# MSP430FR5962 register map
File version: 2.1
CPU: MSP430FR5962 r2p1, little endian, MPU, no FPU, 3 interrupt priority bits
Registers are 16-bit, read-write, reset 0x0 unless marked. A register's access mark holds for its fields unless they carry their own. Offsets are from the block's base; [hi:lo] are bit positions.

## MPY32
Base 0x000004C0
0x00 MPY — 16-bit operand one multiply
0x02 MPYS — 16-bit operand one signed multiply
0x04 MAC — 16-bit operand one multiply accumulate
0x06 MACS — 16-bit operand one signed multiply accumulate
0x08 OP2 — 16-bit operand two
0x0A RESLO — 16x16-bit result low word
0x0C RESHI — 16x16-bit result high word
0x0E SUMEXT — 16x16-bit sum extension register
0x10 MPY32L — 32-bit operand 1 multiply low word
0x12 MPY32H — 32-bit operand 1 multiply high word
0x14 MPYS32L — 32-bit operand 1 signed multiply low word
0x16 MPYS32H — 32-bit operand 1 signed multiply high word
0x18 MAC32L — 32-bit operand 1 multiply accumulate low word
0x1A MAC32H — 32-bit operand 1 multiply accumulate high word
0x1C MACS32L — 32-bit operand 1 signed multiply accumulate low word
0x1E MACS32H — 32-bit operand 1 signed multiply accumulate high word
  [15:8] MACS32H — [15:8] 32-bit operand 1 signed multiply accumulate high word
0x20 OP2L — 32-bit operand 2 low word
0x22 OP2H — 32-bit operand 2 high word
0x24 RES0 — 32x32-bit result 0 least significant word
0x26 RES1 — 32x32-bit result 1
0x28 RES2 — 32x32-bit result 2
0x2A RES3 — 32x32-bit result 3 most significant word
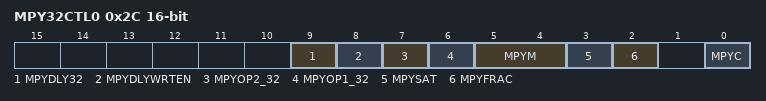
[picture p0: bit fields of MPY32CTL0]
0x2C MPY32CTL0 — MPY32 control register 0
  [9] MPYDLY32 — [9:9] Delayed write mode.
    0=Writes are delayed until 64-bit result (RES0 to RES3) is available; 1=Writes are delayed until 32-bit result (RES0 to RES1) is available. 8 MPYDLYWRTEN
  [8] MPYDLYWRTEN — [8:8] Delayed write enable.
    0=Writes are not delayed; 1=Writes are delayed
  [7] MPYOP2_32 — [7:7] Multiplier bit width of operand 2
    0=16 bits; 1=32 bits
  [6] MPYOP1_32 — [6:6] Multiplier bit width of operand 1
    0=16 bits; 1=32 bits
  [5:4] MPYM — [5:4] Multiplier mode
    0=MPY (MPY Multiply); 1=MPYS (MPYS Signed multiply); 2=MAC (MAC Multiply accumulate); 3=MACS (MACS Signed multiply accumulate)
  [3] MPYSAT — [3:3] Saturation mode
    0=DISABLE (Saturation mode disabled.); 1=ENABLE (Saturation mode enabled.)
  [2] MPYFRAC — [2:2] Fractional mode.
    0=DISABLE (Fractional mode disabled.); 1=ENABLE (Fractional mode enabled.)
  [0] MPYC — [0:0] Carry of the multiplier
    0=No carry for result; 1=Result has a carry

## PMM
Base 0x00000120
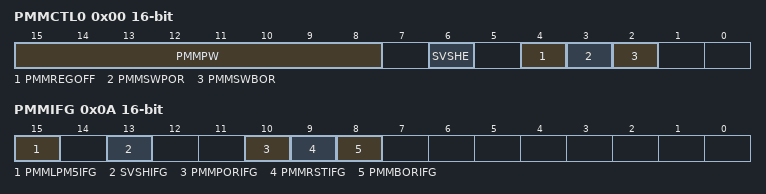
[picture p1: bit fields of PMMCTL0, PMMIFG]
0x00 PMMCTL0 — PMM control register 0
  [15:8] PMMPW — [15:8] PMM password.
  [6] SVSHE — [6:6] High-side SVS enable.
    0=High-side SVS (SVSH) is disabled in LPM2, LPM3, LPM4, LPM3.5, and LPM4.5. SVSH is always enabled in active mode, LPM0, and LPM1.; 1=SVSH is always enabled
  [4] PMMREGOFF — [4:4] Regulator off
    0=Regulator remains on when going into LPM3 or LPM4; 1=Regulator is turned off when going to LPM3 or LPM4. System enters LPM3.5 or LPM4.5, respectively.
  [3] PMMSWPOR — [3:3] Software POR.
    0=Normal operation; 1=Set to 1 to trigger a POR
  [2] PMMSWBOR — [2:2] Software brownout reset.
    0=Normal operation; 1=Set to 1 to trigger a BOR
0x0A PMMIFG — PMM interrupt flag register
  [15] PMMLPM5IFG — [15:15] LPMx.5 flag.
    0=Reset not due to wake-up from LPMx.5; 1=Reset due to wake-up from LPMx.5
  [13] SVSHIFG — [13:13] High-side SVS interrupt flag.
    0=Reset not due to SVSH; 1=Reset due to SVSH
  [10] PMMPORIFG — [10:10] PMM software POR interrupt flag.
    0=PMMBORIFG_0 (Reset not due to PMMSWPOR); 1=PMMBORIFG_1 (Reset due to PMMSWPOR)
  [9] PMMRSTIFG — [9:9] PMM reset pin interrupt flag.
    0=PMMBORIFG_0 (Reset not due to reset pin); 1=PMMBORIFG_1 (Reset due to reset pin)
  [8] PMMBORIFG — [8:8] PMM software brownout reset interrupt flag.
    0=Reset not due to PMMSWBOR; 1=Reset due to PMMSWBOR
0x10 PM5CTL0 — Power mode 5 control register 0
  [0] LOCKLPM5 — [0:0] LPMx.5 Lock Bit
    0=LPMx.5 configuration is not locked and defaults to its reset condition; 1=LPMx.5 configuration remains locked. Pin state is held during LPMx.5 entry and exit.
